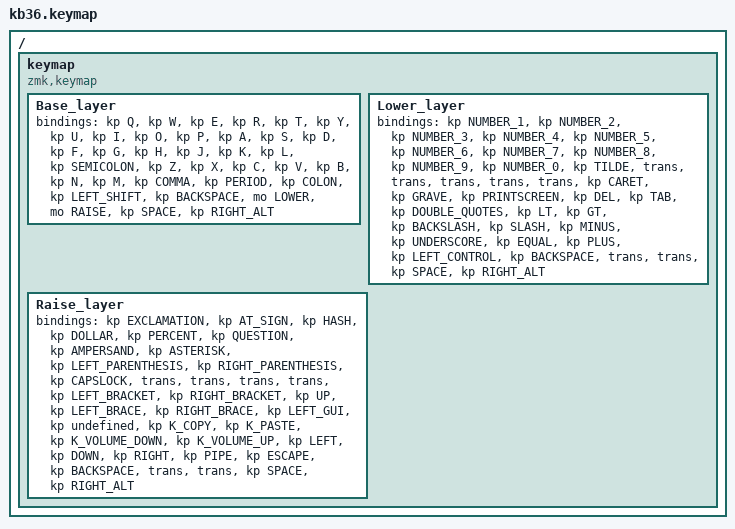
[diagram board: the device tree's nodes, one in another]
#include <behaviors.dtsi>
#include <dt-bindings/zmk/keys.h>

#define BASE 0
#define LOWER 1
#define RAISE 2

/ {
  keymap {
    compatible = "zmk,keymap";

    Base_layer {
      bindings = <
        &kp Q &kp W &kp E &kp R &kp T &kp Y &kp U &kp I &kp O &kp P &kp A &kp S &kp D &kp F &kp G &kp H &kp J &kp K &kp L &kp SEMICOLON &kp Z &kp X &kp C &kp V &kp B &kp N &kp M &kp COMMA &kp PERIOD &kp COLON &kp LEFT_SHIFT &kp BACKSPACE &mo LOWER &mo RAISE &kp SPACE &kp RIGHT_ALT
      >;
    };

    Lower_layer {
      bindings = <
        &kp NUMBER_1 &kp NUMBER_2 &kp NUMBER_3 &kp NUMBER_4 &kp NUMBER_5 &kp NUMBER_6 &kp NUMBER_7 &kp NUMBER_8 &kp NUMBER_9 &kp NUMBER_0 &kp TILDE &trans &trans &trans &trans &trans &kp CARET &kp GRAVE &kp PRINTSCREEN &kp DEL &kp TAB &kp DOUBLE_QUOTES &kp LT &kp GT &kp BACKSLASH &kp SLASH &kp MINUS &kp UNDERSCORE &kp EQUAL &kp PLUS &kp LEFT_CONTROL &kp BACKSPACE &trans &trans &kp SPACE &kp RIGHT_ALT
      >;
    };

    Raise_layer {
      bindings = <
        &kp EXCLAMATION &kp AT_SIGN &kp HASH &kp DOLLAR &kp PERCENT &kp QUESTION &kp AMPERSAND &kp ASTERISK &kp LEFT_PARENTHESIS &kp RIGHT_PARENTHESIS &kp CAPSLOCK &trans &trans &trans &trans &kp LEFT_BRACKET &kp RIGHT_BRACKET &kp UP &kp LEFT_BRACE &kp RIGHT_BRACE &kp LEFT_GUI &kp undefined &kp K_COPY &kp K_PASTE &kp K_VOLUME_DOWN &kp K_VOLUME_UP &kp LEFT &kp DOWN &kp RIGHT &kp PIPE &kp ESCAPE &kp BACKSPACE &trans &trans &kp SPACE &kp RIGHT_ALT
      >;
    };

  };
};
